# ATSAMA5D34 device description
Architecture: CORTEX-A5; Family: SAMA5
Registers are 32-bit, read-write, no defined reset value unless marked. A register's access mark holds for its fields unless they carry their own. Offsets are from the block's base; [hi:lo] are bit positions; {n}, {i} and the like mark numbered series; 'fields as' and 'values as' point back to an identical list.

## SMC — Static Memory Controller
Instances: SMC 0xFFFFC000
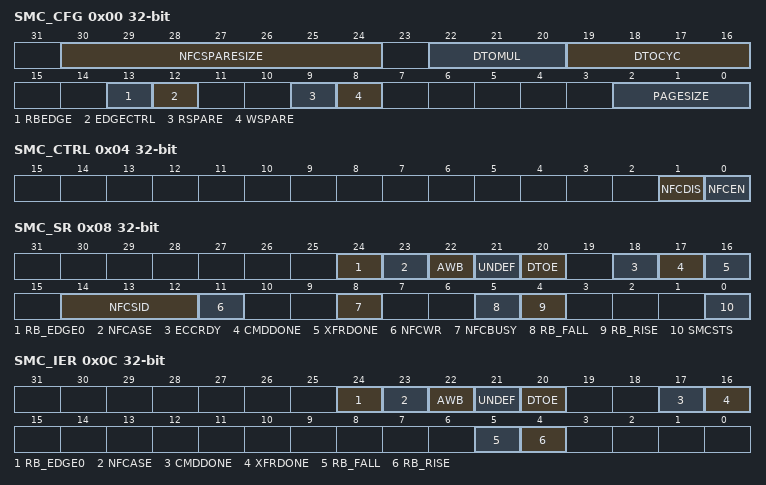
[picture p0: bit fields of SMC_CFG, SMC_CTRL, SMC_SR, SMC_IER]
0x00 SMC_CFG — SMC NFC Configuration Register
  [30:24] NFCSPARESIZE — NAND Flash Spare Area Size Retrieved by the Host Controller
  [22:20] DTOMUL — Data Timeout Multiplier
    0=DTOCYC; 1=X16 (DTOCYC x 16); 2=X128 (DTOCYC x 128); 3=X256 (DTOCYC x 256); 4=X1024 (DTOCYC x 1024); 5=X4096 (DTOCYC x 4096); 6=X65536 (DTOCYC x 65536); 7=X1048576 (DTOCYC x 1048576)
  [19:16] DTOCYC — Data Timeout Cycle Number
  [13] RBEDGE — Ready/Busy Signal Edge Detection
  [12] EDGECTRL — Rising/Falling Edge Detection Control
  [9] RSPARE — Read Spare Area
  [8] WSPARE — Write Spare Area
  [2:0] PAGESIZE
    0=PS512 (Main area 512 Bytes); 1=PS1024 (Main area 1024 Bytes); 2=PS2048 (Main area 2048 Bytes); 3=PS4096 (Main area 4096 Bytes); 4=PS8192 (Main area 8192 Bytes)
0x04 SMC_CTRL wo — SMC NFC Control Register
  [1] NFCDIS — NAND Flash Controller Disable
  [0] NFCEN — NAND Flash Controller Enable
0x08 SMC_SR ro — SMC NFC Status Register
  [24] RB_EDGE0 — Ready/Busy Line 0 Edge Detected
  [23] NFCASE — NFC Access Size Error
  [22] AWB — Accessing While Busy
  [21] UNDEF — Undefined Area Error
  [20] DTOE — Data Timeout Error
  [18] ECCRDY — Hamming ECC Ready
  [17] CMDDONE — Command Done
  [16] XFRDONE — NFC Data Transfer Terminated
  [14:12] NFCSID — NFC Chip Select ID (this field cannot be reset)
  [11] NFCWR — NFC Write/Read Operation (this field cannot be reset)
  [8] NFCBUSY — NFC Busy (this field cannot be reset)
  [5] RB_FALL — Selected Ready Busy Falling Edge Detected
  [4] RB_RISE — Selected Ready Busy Rising Edge Detected
  [0] SMCSTS — NAND Flash Controller Status (this field cannot be reset)
0x0C SMC_IER wo — SMC NFC Interrupt Enable Register
  [24] RB_EDGE0 — Ready/Busy Line 0 Interrupt Enable
  [23] NFCASE — NFC Access Size Error Interrupt Enable
  [22] AWB — Accessing While Busy Interrupt Enable
  [21] UNDEF — Undefined Area Access Interrupt Enable
  [20] DTOE — Data Timeout Error Interrupt Enable
  [17] CMDDONE — Command Done Interrupt Enable
  [16] XFRDONE — Transfer Done Interrupt Enable
  [5] RB_FALL — Ready Busy Falling Edge Detection Interrupt Enable
  [4] RB_RISE — Ready Busy Rising Edge Detection Interrupt Enable
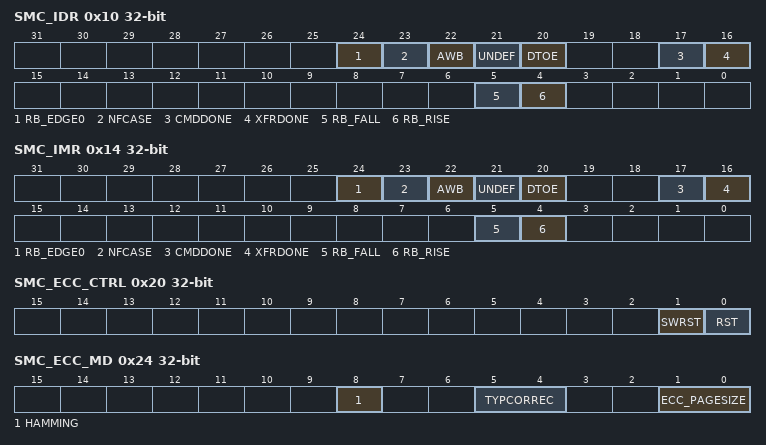
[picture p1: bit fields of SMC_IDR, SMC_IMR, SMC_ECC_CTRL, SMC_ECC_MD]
0x10 SMC_IDR wo — SMC NFC Interrupt Disable Register
  [24] RB_EDGE0 — Ready/Busy Line 0 Interrupt Disable
  [23] NFCASE — NFC Access Size Error Interrupt Disable
  [22] AWB — Accessing While Busy Interrupt Disable
  [21] UNDEF — Undefined Area Access Interrupt Disable
  [20] DTOE — Data Timeout Error Interrupt Disable
  [17] CMDDONE — Command Done Interrupt Disable
  [16] XFRDONE — Transfer Done Interrupt Disable
  [5] RB_FALL — Ready Busy Falling Edge Detection Interrupt Disable
  [4] RB_RISE — Ready Busy Rising Edge Detection Interrupt Disable
0x14 SMC_IMR ro — SMC NFC Interrupt Mask Register
  [24] RB_EDGE0 — Ready/Busy Line 0 Interrupt Mask
  [23] NFCASE — NFC Access Size Error Interrupt Mask
  [22] AWB — Accessing While Busy Interrupt Mask
  [21] UNDEF — Undefined Area Access Interrupt Mask5
  [20] DTOE — Data Timeout Error Interrupt Mask
  [17] CMDDONE — Command Done Interrupt Mask
  [16] XFRDONE — Transfer Done Interrupt Mask
  [5] RB_FALL — Ready Busy Falling Edge Detection Interrupt Mask
  [4] RB_RISE — Ready Busy Rising Edge Detection Interrupt Mask
0x18 SMC_ADDR — SMC NFC Address Cycle Zero Register
  [7:0] ADDR_CYCLE0 — NAND Flash Array Address Cycle 0
0x1C SMC_BANK — SMC Bank Address Register
  [0] BANK — Bank Identifier
0x20 SMC_ECC_CTRL wo — SMC ECC Control Register
  [1] SWRST — Software Reset
  [0] RST — Reset ECC
0x24 SMC_ECC_MD — SMC ECC Mode Register
  [8] HAMMING — Hamming Error Correcting Code Selected
  [5:4] TYPCORREC — Type of Correction
    0=CPAGE (1 bit correction for a page of 512/1024/2048/4096 Bytes (for 8 or 16-bit NAND Flash)); 1=C256B (1 bit correction for 256 Bytes of data for a page of 512/2048/4096 bytes (for 8-bit NAND Flash only)); 2=C512B (1 bit correction for 512 Bytes of data for a page of 512/2048/4096 bytes (for 8-bit NAND Flash only))
  [1:0] ECC_PAGESIZE
    0=PS512 (Main area 512 Words); 1=PS1024 (Main area 1024 Words); 2=PS2048 (Main area 2048 Words); 3=PS4096 (Main area 4096 Words)
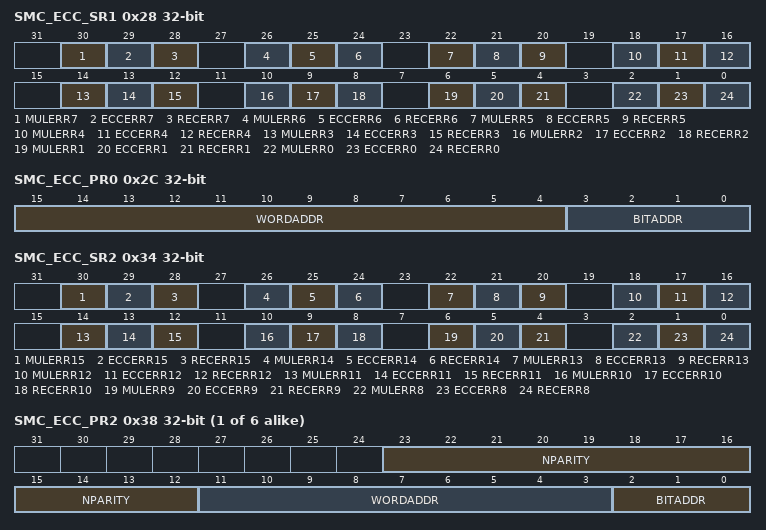
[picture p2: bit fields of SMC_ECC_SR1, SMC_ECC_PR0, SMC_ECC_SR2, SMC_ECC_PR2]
0x28 SMC_ECC_SR1 ro — SMC ECC Status 1 Register
  [30] MULERR7 — Multiple Error in the page between the 1792nd and the 2047th Bytes or between the 3584th and the 4095th Bytes
  [29] ECCERR7 — ECC Error in the page between the 1792nd and the 2047th Bytes or between the 3584th and the 4095th Bytes
  [28] RECERR7 — Recoverable Error in the page between the 1792nd and the 2047th Bytes or between the 3584th and the 4095th Bytes
  [26] MULERR6 — Multiple Error in the page between the 1536th and the 1791st Bytes or between the 3072nd and the 3583rd Bytes
  [25] ECCERR6 — ECC Error in the page between the 1536th and the 1791st Bytes or between the 3072nd and the 3583rd Bytes
  [24] RECERR6 — Recoverable Error in the page between the 1536th and the 1791st Bytes or between the 3072nd and the 3583rd Bytes
  [22] MULERR5 — Multiple Error in the page between the 1280th and the 1535th Bytes or between the 2560th and the 3071st Bytes
  [21] ECCERR5 — ECC Error in the page between the 1280th and the 1535th Bytes or between the 2560th and the 3071st Bytes
  [20] RECERR5 — Recoverable Error in the page between the 1280th and the 1535th Bytes or between the 2560th and the 3071st Bytes
  [18] MULERR4 — Multiple Error in the page between the 1024th and the 1279th Bytes or between the 2048th and the 2559th Bytes
  [17] ECCERR4 — ECC Error in the page between the 1024th and the 1279th Bytes or between the 2048th and the 2559th Bytes
  [16] RECERR4 — Recoverable Error in the page between the 1024th and the 1279th Bytes or between the 2048th and the 2559th Bytes
  [14] MULERR3 — Multiple Error in the page between the 768th and the 1023rd Bytes or between the 1536th and the 2047th Bytes
  [13] ECCERR3 — ECC Error in the page between the 768th and the 1023rd Bytes or between the 1536th and the 2047th Bytes
  [12] RECERR3 — Recoverable Error in the page between the 768th and the 1023rd Bytes or between the 1536th and the 2047th Bytes
  [10] MULERR2 — Multiple Error in the page between the 512nd and the 767th Bytes or between the 1024th and the 1535th Bytes
  [9] ECCERR2 — ECC Error in the page between the 512nd and the 767th Bytes or between the 1024th and the 1535th Bytes
  [8] RECERR2 — Recoverable Error in the page between the 512nd and the 767th Bytes or between the 1024th and the 1535th Bytes
  [6] MULERR1 — Multiple Error in the page between the 256th and the 511th Bytes or between the 512nd and the 1023rd Bytes
  [5] ECCERR1 — ECC Error in the page between the 256th and the 511th Bytes or between the 512nd and the 1023rd Bytes
  [4] RECERR1 — Recoverable Error in the page between the 256th and the 511th Bytes or the 512nd and the 1023rd Bytes
  [2] MULERR0 — Multiple Error
  [1] ECCERR0 — ECC Error
  [0] RECERR0 — Recoverable Error
0x2C SMC_ECC_PR0 ro — SMC ECC Parity 0 Register
  [15:4] WORDADDR — Word Address
  [3:0] BITADDR — Bit Address
0x30 SMC_ECC_PR1 ro — SMC ECC parity 1 Register
  [15:0] NPARITY — Parity N
0x34 SMC_ECC_SR2 ro — SMC ECC status 2 Register
  [30] MULERR15 — Multiple Error in the page between the 3840th and the 4095th Bytes
  [29] ECCERR15 — ECC Error in the page between the 3840th and the 4095th Bytes
  [28] RECERR15 — Recoverable Error in the page between the 3840th and the 4095th Bytes
  [26] MULERR14 — Multiple Error in the page between the 3584th and the 3839th Bytes
  [25] ECCERR14 — ECC Error in the page between the 3584th and the 3839th Bytes
  [24] RECERR14 — Recoverable Error in the page between the 3584th and the 3839th Bytes
  [22] MULERR13 — Multiple Error in the page between the 3328th and the 3583rd Bytes
  [21] ECCERR13 — ECC Error in the page between the 3328th and the 3583rd Bytes
  [20] RECERR13 — Recoverable Error in the page between the 3328th and the 3583rd Bytes
  [18] MULERR12 — Multiple Error in the page between the 3072nd and the 3327th Bytes
  [17] ECCERR12 — ECC Error in the page between the 3072nd and the 3327th Bytes
  [16] RECERR12 — Recoverable Error in the page between the 3072nd and the 3327th Bytes
  [14] MULERR11 — Multiple Error in the page between the 2816th and the 3071st Bytes
  [13] ECCERR11 — ECC Error in the page between the 2816th and the 3071st Bytes
  [12] RECERR11 — Recoverable Error in the page between the 2816th and the 3071st Bytes
  [10] MULERR10 — Multiple Error in the page between the 2560th and the 2815th Bytes
  [9] ECCERR10 — ECC Error in the page between the 2560th and the 2815th Bytes
  [8] RECERR10 — Recoverable Error in the page between the 2560th and the 2815th Bytes
  [6] MULERR9 — Multiple Error in the page between the 2304th and the 2559th Bytes
  [5] ECCERR9 — ECC Error in the page between the 2304th and the 2559th Bytes
  [4] RECERR9 — Recoverable Error in the page between the 2304th and the 2559th Bytes
  [2] MULERR8 — Multiple Error in the page between the 2048th and the 2303rd Bytes
  [1] ECCERR8 — ECC Error in the page between the 2048th and the 2303rd Bytes
  [0] RECERR8 — Recoverable Error in the page between the 2048th and the 2303rd Bytes
{0x30+4i} SMC_ECC_PR{i} ro (i=2..7) — SMC ECC parity {i} Register
  [23:12] NPARITY — Parity N
  [11:3] WORDADDR — Corrupted Word Address in the Page between (i x 512) and ((i + 1) x 512) - 1) Bytes
  [2:0] BITADDR — Corrupted Bit Address in the Page between (i x 512) and ((i + 1) x 512) - 1) Bytes
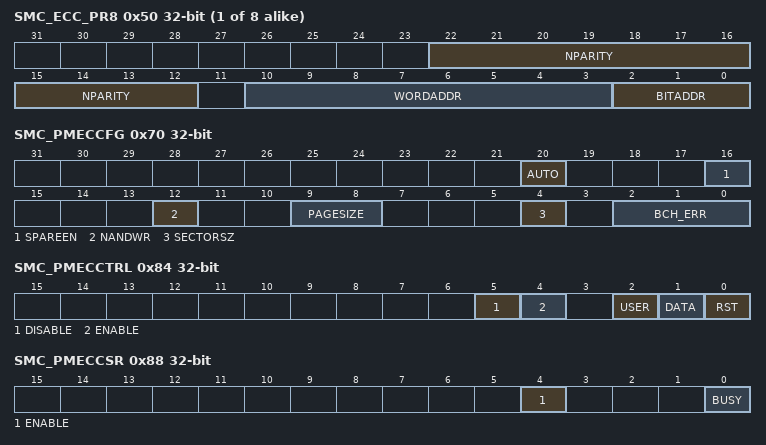
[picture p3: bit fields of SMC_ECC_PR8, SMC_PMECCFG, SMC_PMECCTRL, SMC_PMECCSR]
{0x30+4i} SMC_ECC_PR{i} ro (i=8..15) — SMC ECC parity {i} Register
  [22:12] NPARITY — Parity N
  [10:3] WORDADDR — Corrupted Word Address in the Page between (i x 256) and ((i + 1) x 512) - 1) Bytes
  [2:0] BITADDR — Corrupted Bit Address in the Page between (i x 256) and ((i + 1) x 512) - 1) Bytes
0x70 SMC_PMECCFG — PMECC Configuration Register
  [20] AUTO — Automatic Mode Enable
  [16] SPAREEN — Spare Enable
  [12] NANDWR — NAND Write Access
  [9:8] PAGESIZE — Number of Sectors in the Page
    0=PAGESIZE_1SEC (1 sector for main area (512 or 1024 Bytes)); 1=PAGESIZE_2SEC (2 sectors for main area (1024 or 2048 Bytes)); 2=PAGESIZE_4SEC (4 sectors for main area (2048 or 4096 Bytes)); 3=PAGESIZE_8SEC (8 sectors for main area (4096 or 8192 Bytes))
  [4] SECTORSZ — Sector Size
  [2:0] BCH_ERR — Error Correcting Capability
    0=2 errors; 1=4 errors; 2=8 errors; 3=12 errors; 4=24 errors
0x74 SMC_PMECCSAREA — PMECC Spare Area Size Register
  [8:0] SPARESIZE — Spare Area Size
0x78 SMC_PMECCSADDR — PMECC Start Address Register
  [8:0] STARTADDR — ECC Area Start Address
0x7C SMC_PMECCEADDR — PMECC End Address Register
  [8:0] ENDADDR — ECC Area End Address
0x84 SMC_PMECCTRL wo — PMECC Control Register
  [5] DISABLE — PMECC Enable
  [4] ENABLE — PMECC Enable
  [2] USER — Start a User Mode Phase
  [1] DATA — Start a Data Phase
  [0] RST — Reset the PMECC Module
0x88 SMC_PMECCSR ro — PMECC Status Register
  [4] ENABLE — PMECC Enable bit
  [0] BUSY — The kernel of the PMECC is busy
0x8C SMC_PMECCIER wo — PMECC Interrupt Enable register
  [0] ERRIE — Error Interrupt Enable
0x90 SMC_PMECCIDR wo — PMECC Interrupt Disable Register
  [0] ERRID — Error Interrupt Disable
0x94 SMC_PMECCIMR ro — PMECC Interrupt Mask Register
  [0] ERRIM — Error Interrupt Mask
0x98 SMC_PMECCISR ro — PMECC Interrupt Status Register
  [7:0] ERRIS — Error Interrupt Status Register
{0xB0+4i} SMC_PMECC{i}_0 ro (i=0..10) — PMECC Redundancy {i} Register (sec_num = 0)
  [31:0] ECC — BCH Redundancy
{0xF0+4i} SMC_PMECC{i}_1 ro (i=0..10) — PMECC Redundancy {i} Register (sec_num = 1)
  [31:0] ECC — BCH Redundancy
{0x130+4i} SMC_PMECC{i}_2 ro (i=0..10) — PMECC Redundancy {i} Register (sec_num = 2)
  [31:0] ECC — BCH Redundancy
{0x170+4i} SMC_PMECC{i}_3 ro (i=0..10) — PMECC Redundancy {i} Register (sec_num = 3)
  [31:0] ECC — BCH Redundancy
{0x1B0+4i} SMC_PMECC{i}_4 ro (i=0..10) — PMECC Redundancy {i} Register (sec_num = 4)
  [31:0] ECC — BCH Redundancy
{0x1F0+4i} SMC_PMECC{i}_5 ro (i=0..10) — PMECC Redundancy {i} Register (sec_num = 5)
  [31:0] ECC — BCH Redundancy
{0x230+4i} SMC_PMECC{i}_6 ro (i=0..10) — PMECC Redundancy {i} Register (sec_num = 6)
  [31:0] ECC — BCH Redundancy
{0x270+4i} SMC_PMECC{i}_7 ro (i=0..10) — PMECC Redundancy {i} Register (sec_num = 7)
  [31:0] ECC — BCH Redundancy
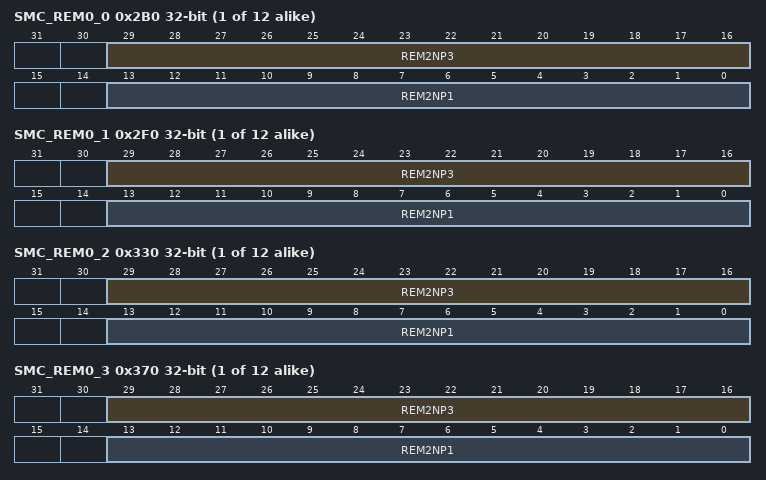
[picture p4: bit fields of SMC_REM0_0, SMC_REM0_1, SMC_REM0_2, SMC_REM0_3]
{0x2B0+4i} SMC_REM{i}_0 ro (i=0..11) — PMECC Remainder {i} Register (sec_num = 0)
  [29:16] REM2NP3 — BCH Remainder 2 * N + 3
  [13:0] REM2NP1 — BCH Remainder 2 * N + 1
{0x2F0+4i} SMC_REM{i}_1 ro (i=0..11) — PMECC Remainder {i} Register (sec_num = 1)
  fields as SMC_REM0_0
{0x330+4i} SMC_REM{i}_2 ro (i=0..11) — PMECC Remainder {i} Register (sec_num = 2)
  fields as SMC_REM0_0
{0x370+4i} SMC_REM{i}_3 ro (i=0..11) — PMECC Remainder {i} Register (sec_num = 3)
  fields as SMC_REM0_0
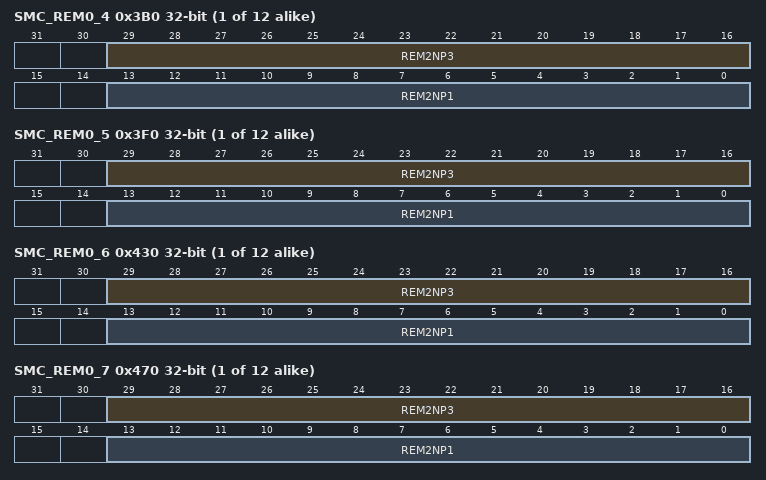
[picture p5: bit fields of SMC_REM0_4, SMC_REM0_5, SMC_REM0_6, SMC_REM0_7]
{0x3B0+4i} SMC_REM{i}_4 ro (i=0..11) — PMECC Remainder {i} Register (sec_num = 4)
  fields as SMC_REM0_0
{0x3F0+4i} SMC_REM{i}_5 ro (i=0..11) — PMECC Remainder {i} Register (sec_num = 5)
  fields as SMC_REM0_0
{0x430+4i} SMC_REM{i}_6 ro (i=0..11) — PMECC Remainder {i} Register (sec_num = 6)
  fields as SMC_REM0_0
{0x470+4i} SMC_REM{i}_7 ro (i=0..11) — PMECC Remainder {i} Register (sec_num = 7)
  fields as SMC_REM0_0
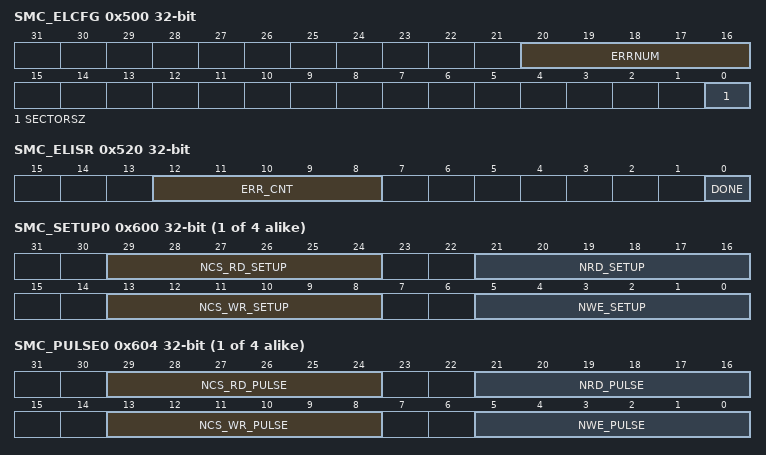
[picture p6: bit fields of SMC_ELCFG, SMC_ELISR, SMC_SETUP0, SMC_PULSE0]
0x500 SMC_ELCFG — PMECC Error Location Configuration Register
  [20:16] ERRNUM — Number of Errors
  [0] SECTORSZ — Sector Size
0x504 SMC_ELPRIM ro — PMECC Error Location Primitive Register
  [15:0] PRIMITIV — Primitive Polynomial
0x508 SMC_ELEN wo — PMECC Error Location Enable Register
  [13:0] ENINIT — Error Location Enable
0x50C SMC_ELDIS wo — PMECC Error Location Disable Register
  [0] DIS — Disable Error Location Engine
0x510 SMC_ELSR ro — PMECC Error Location Status Register
  [0] BUSY — Error Location Engine Busy
0x514 SMC_ELIER wo — PMECC Error Location Interrupt Enable register
  [0] DONE — Computation Terminated Interrupt Enable
0x518 SMC_ELIDR wo — PMECC Error Location Interrupt Disable Register
  [0] DONE — Computation Terminated Interrupt Disable
0x51C SMC_ELIMR ro — PMECC Error Location Interrupt Mask Register
  [0] DONE — Computation Terminated Interrupt Mask
0x520 SMC_ELISR ro — PMECC Error Location Interrupt Status Register
  [12:8] ERR_CNT — Error Counter value
  [0] DONE — Computation Terminated Interrupt Status
{0x528+4i} SMC_SIGMA{i} (i=0..24) — PMECC Error Location SIGMA {i} Register
  [13:0] SIGMA{i} — Coefficient of degree x in the SIGMA polynomial.
{0x58C+4i} SMC_ERRLOC{i} ro (i=0..23) — PMECC Error Location 0 Register {i}
  [13:0] ERRLOCN — Error Position within the Set {sector area, spare area}
{0x600+0x14*i} SMC_SETUP{i} (i=0..3) — SMC Setup Register (CS_number = {i})
  [29:24] NCS_RD_SETUP — NCS Setup Length in Read Access
  [21:16] NRD_SETUP — NRD Setup Length
  [13:8] NCS_WR_SETUP — NCS Setup Length in Write Access
  [5:0] NWE_SETUP — NWE Setup Length
{0x604+0x14*i} SMC_PULSE{i} (i=0..3) — SMC Pulse Register (CS_number = {i})
  [29:24] NCS_RD_PULSE — NCS Pulse Length in READ Access
  [21:16] NRD_PULSE — NRD Pulse Length
  [13:8] NCS_WR_PULSE — NCS Pulse Length in WRITE Access
  [5:0] NWE_PULSE — NWE Pulse Length
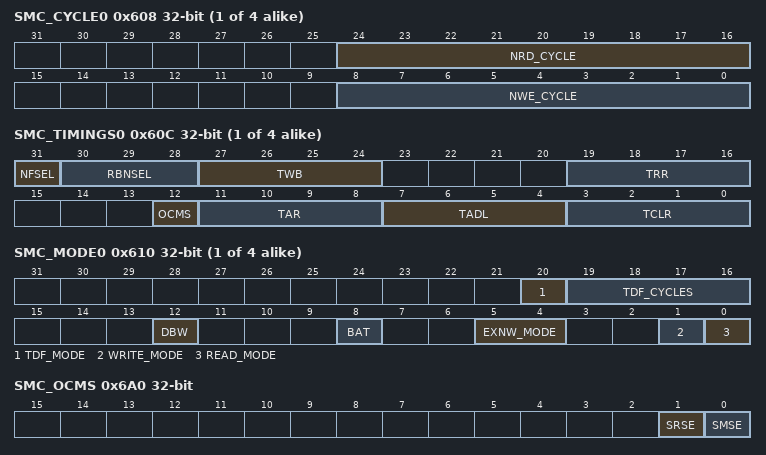
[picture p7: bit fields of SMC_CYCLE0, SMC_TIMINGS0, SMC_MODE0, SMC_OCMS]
{0x608+0x14*i} SMC_CYCLE{i} (i=0..3) — SMC Cycle Register (CS_number = {i})
  [24:16] NRD_CYCLE — Total Read Cycle Length
  [8:0] NWE_CYCLE — Total Write Cycle Length
{0x60C+0x14*i} SMC_TIMINGS{i} (i=0..3) — SMC Timings Register (CS_number = {i})
  [31] NFSEL — NAND Flash Selection
  [30:28] RBNSEL — Ready/Busy Line Selection
  [27:24] TWB — WEN High to REN to Busy
  [19:16] TRR — Ready to REN Low Delay
  [12] OCMS — Off Chip Memory Scrambling Enable
  [11:8] TAR — ALE to REN Low Delay
  [7:4] TADL — ALE to Data Start
  [3:0] TCLR — CLE to REN Low Delay
{0x610+0x14*i} SMC_MODE{i} (i=0..3) — SMC Mode Register (CS_number = {i})
  [20] TDF_MODE — TDF Optimization
  [19:16] TDF_CYCLES — Data Float Time
  [12] DBW — Data Bus Width
    0=BIT_8 (8-bit bus); 1=BIT_16 (16-bit bus)
  [8] BAT — Byte Access Type
  [5:4] EXNW_MODE — NWAIT Mode
    0=DISABLED; 2=FROZEN (Frozen Mode); 3=READY (Ready Mode)
  [1] WRITE_MODE
    0=NCS_CTRL (The Write operation is controller by the NCS signal.); 1=NWE_CTRL (The Write operation is controlled by the NWE signal.)
  [0] READ_MODE
    0=NCS_CTRL (The Read operation is controlled by the NCS signal.); 1=NRD_CTRL (The Read operation is controlled by the NRD signal.)
0x6A0 SMC_OCMS
  [1] SRSE — SRAM Scrambling Enable
  [0] SMSE — Static Memory Controller Scrambling Enable
0x6A4 SMC_KEY1 wo — SMC OCMS KEY1 Register
  [31:0] KEY1 — Off Chip Memory Scrambling (OCMS) Key Part 1
0x6A8 SMC_KEY2 wo — SMC OCMS KEY2 Register
  [31:0] KEY2 — Off Chip Memory Scrambling (OCMS) Key Part 2
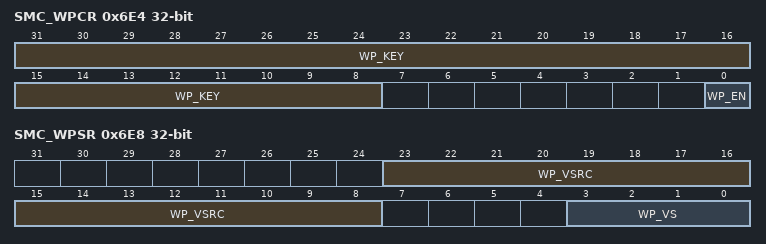
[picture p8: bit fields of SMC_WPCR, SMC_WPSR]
0x6E4 SMC_WPCR wo — SMC Write Protection Control Register
  [31:8] WP_KEY — Write Protection KEY password
  [0] WP_EN — Write Protection Enable
0x6E8 SMC_WPSR ro — SMC Write Protection Status Register
  [23:8] WP_VSRC — Write Protection Violation Source
  [3:0] WP_VS — Write Protection Violation Status
